# STM32MP23_CM33 register map
File version: 1.2
CPU: CM33 r0p1, little endian, MPU, FPU, vendor SysTick, 8 interrupt priority bits
Registers are 32-bit, read-write, reset 0x0 unless marked. A register's access mark holds for its fields unless they carry their own. Offsets are from the block's base; [hi:lo] are bit positions; {n}, {i} and the like mark numbered series; 'fields as' and 'values as' point back to an identical list.

## RAMCFG — RAMCFG register bank
Base 0x42070000
Same registers: RAMCFG_S 0x52070000
0x00 RAMCFG_SYSRAMCR — RAMCFG SYSRAM control register
  [8] SRAMER — SRAM erase This bit can be set by software only after writing the unlock sequence in ERASEKEY of RAMCFG_SYSRAMERASEKEY. Setting this bit starts the SRAM erase. This bit is automatically cleared by hardware at the end of the erase operation.
    0=No erase operation ongoing; 1=Erase operation ongoing
0x08 RAMCFG_SYSRAMISR ro — RAMCFG SYSRAM interrupt status register
  [8] SRAMBUSY — SRAM busy with erase operation Note: Depending on the SRAM, the erase operation can be performed due to software request, system reset if the option is not disabled by software and tamper detection. Refer to Table73: Internal SRAM features.
    0=No erase operation ongoing; 1=Erase operation ongoing
0x28 RAMCFG_SYSRAMERKEYR wo — RAMCFG SYSRAM erase key register
  [7:0] ERASEKEY — Erase write protection key The following steps are required to unlock the write protection of SRAMER in RAMCFG_SYSRAMCR. a) Write 0xCA into ERASEKEY[7:0]. b) Write 0x53 into ERASEKEY[7:0]. Note: Writing a wrong key reactivates the write protection.
0x80 RAMCFG_SRAM1CR — RAMCFG SRAM1 control register
  [8] SRAMER — SRAM erase. This bit can be set by software only after writing the unlock sequence in ERASEKEY of RAMCFG_MCURAM1ERASEKEY. Setting this bit starts the SRAM erase. This bit is automatically cleared by hardware at the end of the erase operation.
    0=No erase operation ongoing; 1=Erase operation ongoing
0x88 RAMCFG_SRAM1ISR ro — RAMCFG SRAM1 interrupt status register
  fields as RAMCFG_SYSRAMISR
0xA8 RAMCFG_SRAM1ERKEYR wo — RAMCFG SRAM1 erase key register
  [7:0] ERASEKEY — Erase write protection key The following steps are required to unlock the write protection of SRAMER in RAMCFG_MCURAM1CR. a) Write 0xCA into ERASEKEY[7:0]. b) Write 0x53 into ERASEKEY[7:0]. Note: Writing a wrong key reactivates the write protection.
0x100 RAMCFG_SRAM2CR — RAMCFG SRAM2 control register
  [8] SRAMER — SRAM erase. This bit can be set by software only after writing the unlock sequence in ERASEKEY of RAMCFG_MCURAM2ERASEKEY. Setting this bit starts the SRAM erase. This bit is automatically cleared by hardware at the end of the erase operation.
    0=No erase operation ongoing; 1=Erase operation ongoing
0x108 RAMCFG_SRAM2ISR ro — RAMCFG SRAM2 interrupt status register
  [8] SRAMBUSY — SRAM busy with erase operation Note: Depending on the SRAM, the erase operation can be performed due to software request, system reset if the option is not disabled by software and tamper detection. Refer to Table73: Internal SRAM features.
    0=No erase operation on going; 1=Erase operation on going
0x128 RAMCFG_SRAM2ERKEYR wo — RAMCFG SRAM2 erase key register
  [7:0] ERASEKEY — Erase write protection key The following steps are required to unlock the write protection of SRAMER in RAMCFG_MCURAM2CR. a) Write 0xCA into ERASEKEY[7:0]. b) Write 0x53 into ERASEKEY[7:0]. Note: Writing a wrong key reactivates the write protection.
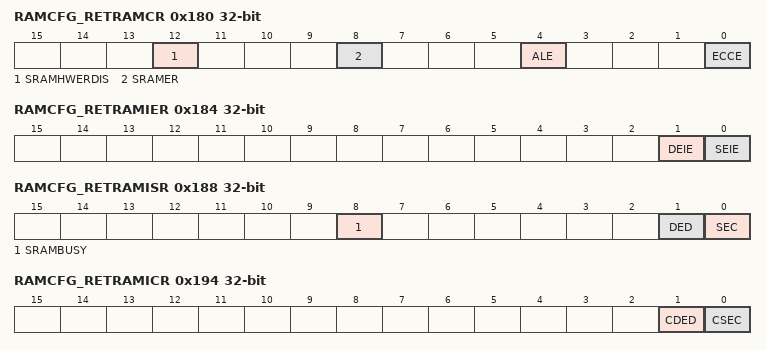
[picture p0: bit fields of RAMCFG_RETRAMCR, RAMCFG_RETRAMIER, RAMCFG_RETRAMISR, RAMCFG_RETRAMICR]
0x180 RAMCFG_RETRAMCR — RAMCFG RETRAM control register
  [12] SRAMHWERDIS — SRAM hardware erase disable Note: This bit is reset on a reset only by VSW POR and VSWRST.
    0=Erase operation done after a system reset; 1=No erase operation done after a system reset
  [8] SRAMER — SRAM erase. This bit can be set by software only after writing the unlock sequence in ERASEKEY of RAMCFG_RETRAMERASEKEY. Setting this bit starts the SRAM erase. This bit is automatically cleared by hardware at the end of the erase operation. Note: This bit is reset on any system reset.
    0=No erase operation ongoing; 1=Erase operation ongoing
  [4] ALE — Address latch enable Note: This bit is reset on any system reset.
    0=Failing address not stored in the RETRAMECC single/double error address registers; 1=Failing address stored in the RETRAMECC single/double error address registers
  [0] ECCE — ECC enable When set, this bit can be cleared by software only after writing the unlock sequence inRAMCFG_RETRAMECCKEYR. Note: This bit is reset on an application reset.
    0=ECC disabled; 1=ECC enabled
0x184 RAMCFG_RETRAMIER — RAMCFG RETRAM interrupt enable register
  [1] DEIE — ECC double error interrupt enable
    0=Double error interrupt disabled; 1=Double error interrupt enabled
  [0] SEIE — ECC single error interrupt enable
    0=Single error interrupt disabled; 1=Single error interrupt enabled
0x188 RAMCFG_RETRAMISR ro — RAMCFG RETRAM interrupt status register
  [8] SRAMBUSY — SRAM busy with erase operation Note: Depending on the SRAM, the erase operation can be performed due to software request, system reset if the option is not disabled by software and tamper detection. Refer to Table73: Internal SRAM features.
    0=No erase operation ongoing; 1=Erase operation ongoing
  [1] DED — ECC double error detected
    0=No double error; 1=Double error detected
  [0] SEC — ECC single error corrected
    0=No single error; 1=Single error corrected
0x18C RAMCFG_RETRAMSEAR ro — RAMCFG RETRAM ECC single error address register
  [14:0] ESEA — ECC single error address When ALE is set in RAMCFG_RETRAMCR, this bit field is updated with the word-address corresponding to the ECC single error.
0x190 RAMCFG_RETRAMDEAR ro — RAMCFG RETRAM ECC double error address register
  [14:0] EDEA — ECC double error address When ALE is set in RAMCFG_RETRAMCR, this bit field is updated with the word-address corresponding to the ECC double error.
0x194 RAMCFG_RETRAMICR wo — RAMCFG RETRAM interrupt clear flag register
  [1] CDED — Clear of ECC double error detected Writing 1 to this flag clears DED in RAMCFG_RETRAMISR.
  [0] CSEC — Clear of ECC single corrected Writing 1 to this flag clears SEC in RAMCFG_RETRAMISR.
0x1A4 RAMCFG_RETRAMECCKEYR wo — RAMCFG RETRAM ECC key register
  [7:0] ECCKEY — ECC write protection key The following steps are required to unlock the write protection of ECCE in RAMCFG_RETRAMCR. a) Write 0xAE into ECCKEY[7:0]. b) Write 0x75 into ECCKEY[7:0]. Note: Writing a wrong key reactivates the write protection.
0x1A8 RAMCFG_RETRAMERKEYR wo — RAMCFG RETRAM erase key register
  [7:0] ERASEKEY — Erase write protection key The following steps are required to unlock the write protection of SRAMER in RAMCFG_RETRAMCR. a) Write 0xCA into ERASEKEY[7:0]. b) Write 0x53 into ERASEKEY[7:0]. Note: Writing a wrong key reactivates the write protection.
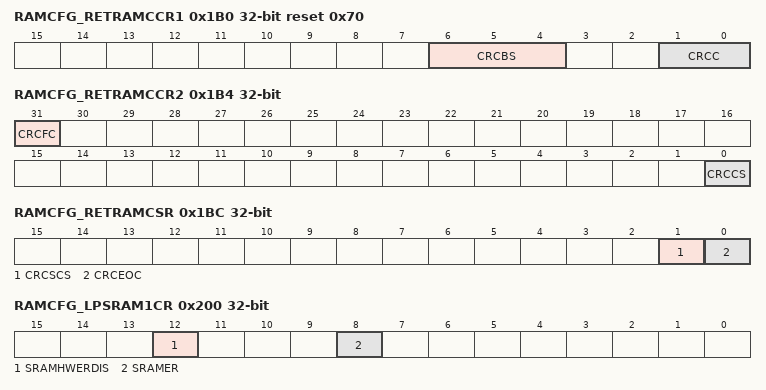
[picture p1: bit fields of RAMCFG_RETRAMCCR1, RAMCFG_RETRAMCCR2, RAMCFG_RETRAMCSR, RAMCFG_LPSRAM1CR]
0x1B0 RAMCFG_RETRAMCCR1 reset 0x70 — RAMCFG RETRAM CRC control register 1
  [6:4] CRCBS — CRC buffer size This bit field is used to program the buffer size to take into account during CRC computation. Starting from RETRAM start address. .....
    0=16 Kbytes; 1=32 Kbytes; 2=48 Kbytes; 7=128 Kbytes (default)
  [1:0] CRCC — CRC configuration. in RAMCFG_RETRAMCCSR when the CRCEOC flag is set.
    0=CRC disabled; 1=CRC computation enabled. The calculated signature is stored; 2=CRC computation and signature check enabled. The status of the signature check is available in RAMCFG_RETRAMCSR when the CRCEOC flag is set.
0x1B4 RAMCFG_RETRAMCCR2 — RAMCFG RETRAM CRC control register 2
  [31] CRCFC — CRC flags clear. Setting this bit clears the CRC status flags in RAMCFG_RETRAMCSR. Note: This bit is automatically cleared by hardware.
    0=CRC flags are not affected; 1=CRC flags are cleared in RAMCFG_RETRAMCSR
  [0] CRCCS — CRC computation start Setting this bit starts the CRC computation. This bit is automatically cleared by hardware at the end of the CRC computation phase.
    0=CRC computation not launched; 1=CRC computation launched
0x1B8 RAMCFG_RETRAMCRSR — RAMCFG RETRAM CRC reference signature register
  [31:0] CRCRS — CRC reference signature. This bit field is used to write the reference signature (precalculated signature) used for CRC signature comparison check.
0x1BC RAMCFG_RETRAMCSR ro — RAMCFG RETRAM CRC status register
  [1] CRCSCS — CRC signature check status flag This bit is set when the computed signature matches the reference signature stored in RAMCFG_RETRAMCRSR. This bit is valid only when the CRCEOC flag is set.
    0=Fault detected is SRAM data. Calculated signature does not match the reference signature.; 1=SRAM data is correct. Calculated signature matches the reference signature.
  [0] CRCEOC — CRC end-of-computation flag
    0=Computation ongoing; 1=Computation done
0x1C0 RAMCFG_RETRAMCCSR ro — RAMCFG RETRAM CRC calculated signature register
  [31:0] CRCCS — CRC calculated signature When CRCEOC is set in RAMCFG_RETRAMCSR, this bit field is updated with the calculate signature representing the content of the SRAM buffer to compute.
0x200 RAMCFG_LPSRAM1CR — RAMCFG LPSRAM1 control register
  [12] SRAMHWERDIS — SRAM hardware erase disable Note: This bit is reset on a reset only by VSW POR and VSWRST.
    0=Erase operation done after a D3 domain reset; 1=No erase operation done after a D3 domain reset
  [8] SRAMER — SRAM erase. This bit can be set by software only after writing the unlock sequence in ERASEKEY of RAMCFG_LPSRAM1ERASEKEY. Setting this bit starts the SRAM erase. This bit is automatically cleared by hardware at the end of the erase operation. Note: This bit is reset on any system reset.
    0=No erase operation ongoing; 1=Erase operation ongoing
{0x188+0x80*i} RAMCFG_LPSRAM{i}ISR ro (i=1..3) — RAMCFG LPSRAM{i} interrupt status register
  fields as RAMCFG_SYSRAMISR
{0x1A8+0x80*i} RAMCFG_LPSRAM{i}ERKEYR wo (i=1..3) — RAMCFG LPSRAM{i} erase key register
  [7:0] ERASEKEY — Erase write protection key The following steps are required to unlock the write protection of SRAMER in RAMCFG_LPSRAM{i}CR. a) Write 0xCA into ERASEKEY[7:0]. b) Write 0x53 into ERASEKEY[7:0]. Note: Writing a wrong key reactivates the write protection.
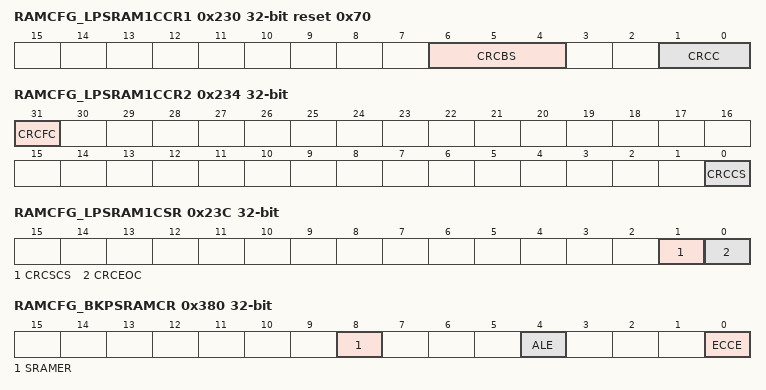
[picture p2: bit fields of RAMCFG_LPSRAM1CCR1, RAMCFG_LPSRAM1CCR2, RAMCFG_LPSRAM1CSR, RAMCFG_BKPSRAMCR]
0x230 RAMCFG_LPSRAM1CCR1 reset 0x70 — RAMCFG LPSRAM1 CRC control register 1
  [6:4] CRCBS — CRC buffer size This bit field is used to program the buffer size to take into account during CRC computation. Starting from LPSRAM1 start address. .....
    0=1 Kbyte; 1=2 Kbytes; 2=3 Kbytes; 7=8 Kbytes (default)
  [1:0] CRCC — CRC configuration. in RAMCFG_LPSRAM1CCSR when the CRCEOC flag is set.
    0=CRC disabled; 1=CRC computation enabled. The calculated signature is stored; 2=CRC computation and signature check enabled. The status of the signature check is available in RAMCFG_LPSRAM1CSR when the CRCEOC flag is set.
0x234 RAMCFG_LPSRAM1CCR2 — RAMCFG LPSRAM1 CRC control register 2
  [31] CRCFC — CRC flags clear. Setting this bit clears the CRC status flags C in RAMCFG_LPSRAM1CSR. Note: This bit is automatically cleared by hardware.
    0=CRC flags are not affected; 1=CRC flags are cleared in RAMCFG_LPSRAM1CSR
  [0] CRCCS — CRC computation start Setting this bit starts the CRC computation. This bit is automatically cleared by hardware at the end of the CRC computation phase.
    0=CRC computation not launched; 1=CRC computation launched
0x238 RAMCFG_LPSRAM1CRSR — RAMCFG LPSRAM1 CRC reference signature register
  fields as RAMCFG_RETRAMCRSR
0x23C RAMCFG_LPSRAM1CSR ro — RAMCFG LPSRAM1 CRC status register
  [1] CRCSCS — CRC signature check status flag This bit is set when the computed signature matches the reference signature stored in RAMCFG_LPSRAM1CRSR. This field is valid only when the CRCEOC flag is set.
    0=Fault detected is SRAM data. Calculated signature does not matching the reference signature.; 1=SRAM data is correct. Calculated signature matches the reference signature.
  [0] CRCEOC — CRC end of computation flag
    0=Computation ongoing; 1=Computation done
0x240 RAMCFG_LPSRAM1CCSR ro — RAMCFG LPSRAM1 CRC calculated signature register
  [31:0] CRCCS — CRC calculated signature When CRCEOC is set in RAMCFG_LPSRAM1CSR, this field is updated with the calculate signature representing the content of the SRAM buffer to compute.
0x280 RAMCFG_LPSRAM2CR — RAMCFG LPSRAM2 control register
  [8] SRAMER — SRAM erase. This bit can be set by software only after writing the unlock sequence in the ERASEKEY field of RAMCFG_LPSRAM2ERASEKEY. Setting this bit starts the SRAM erase. This bit is automatically cleared by hardware at the end of the erase operation.
    0=No erase operation ongoing; 1=Erase operation ongoing
0x300 RAMCFG_LPSRAM3CR — RAMCFG LPSRAM3 control register
  [8] SRAMER — SRAM erase. This bit can be set by software only after writing the unlock sequence in ERASEKEY of RAMCFG_LPSRAM3ERASEKEY. Setting this bit starts the SRAM erase. This bit is automatically cleared by hardware at the end of the erase operation.
    0=No erase operation ongoing; 1=Erase operation ongoing
0x380 RAMCFG_BKPSRAMCR — RAMCFG BKPSRAM control register
  [8] SRAMER — SRAM erase. This bit can be set by software only after writing the unlock sequence in ERASEKEY of RAMCFG_BKPSRAMERASEKEY. Setting this bit starts the SRAM erase. This bit is automatically cleared by hardware at the end of the erase operation.
    0=No erase operation ongoing; 1=Erase operation ongoing
  [4] ALE — Address latch enable
    0=Failing address not stored in the BKPSRAMECC single/double error address registers; 1=Failing address stored in the BKPSRAMECC single/double error address registers
  [0] ECCE — ECC enable When set, this bit can be cleared by software only after writing the unlock sequence in RAMCFG_BKPSRAMECCKEYR.
    0=ECC disabled; 1=ECC enabled
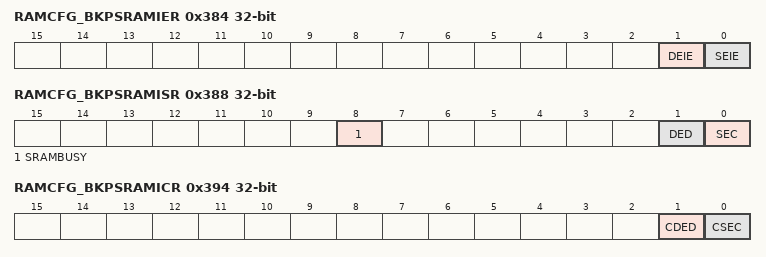
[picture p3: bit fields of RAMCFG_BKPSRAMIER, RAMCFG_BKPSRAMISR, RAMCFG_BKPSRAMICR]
0x384 RAMCFG_BKPSRAMIER — RAMCFG BKPSRAM interrupt enable register
  [1] DEIE — ECC double-error interrupt enable
    0=Double-error interrupt disabled; 1=Double-error interrupt enabled
  [0] SEIE — ECC single-error interrupt enable
    0=Single-error interrupt disabled; 1=Single-error interrupt enabled
0x388 RAMCFG_BKPSRAMISR ro — RAMCFG BKPSRAM interrupt status register
  [8] SRAMBUSY — SRAM busy with erase operation Note: Depending on the SRAM, the erase operation can be performed due to software request, system reset if the option is not disabled by software and tamper detection. Refer to Table73: Internal SRAM features.
    0=No erase operation ongoing; 1=Erase operation ongoing
  [1] DED — ECC double error detected
    0=No double error; 1=Double error detected
  [0] SEC — ECC single error corrected
    0=No single error; 1=Single error detected and corrected
0x38C RAMCFG_BKPSRAMEEAR ro — RAMCFG BKPSRAM ECC single error address register
  [10:0] ESEA — ECC single error address When ALE is set in RAMCFG_BKPSRAMCR, this field is updated with the word-address corresponding to the ECC single error.
0x390 RAMCFG_BKPSRAMDEAR ro — RAMCFG BKPSRAM ECC double error address register
  [10:0] EDEA — ECC double error address When ALE is set in RAMCFG_BKPSRAMCR, this bit field is updated with the word-address corresponding to the ECC double error.
0x394 RAMCFG_BKPSRAMICR wo — RAMCFG BKPSRAM interrupt clear flag register
  [1] CDED — Clear of ECC double error detected Writing 1 to this flag clears DED in RAMCFG_BKPSRAMISR.
  [0] CSEC — Clear of ECC single corrected Writing 1 to this flag clears SEC in RAMCFG_BKPSRAMISR.
0x3A4 RAMCFG_BKPSRAMECCKEYR wo — RAMCFG BKPSRAM ECC key register
  [7:0] ECCKEY — ECC write protection key The following steps are required to unlock the write protection of ECCE in RAMCFG_BKPSRAMCR. a) Write 0xAE into ECCKEY[7:0]. b) Write 0x75 into ECCKEY[7:0]. Note: Writing a wrong key reactivates the write protection.
0x3A8 RAMCFG_BKPSRAMERKEYR wo — RAMCFG BKPSRAM erase key register
  [7:0] ERASEKEY — Erase write protection key The following steps are required to unlock the write protection of SRAMER in RAMCFG_BKPSRAMCR. a) Write 0xCA into ERASEKEY[7:0]. b) Write 0x53 into ERASEKEY[7:0]. Note: Writing a wrong key reactivates the write protection.
0x400 RAMCFG_VDERAMCR — RAMCFG VDERAM control register
  [8] SRAMER — SRAM erase This bit can be set by software only after writing the unlock sequence in ERASEKEY of RAMCFG_VDERAMERASEKEY. Setting this bit starts the SRAM erase. This bit is automatically cleared by hardware at the end of the erase operation. Note: This bit is reset on any system reset.
    0=No erase operation ongoing; 1=Erase operation ongoing
0x408 RAMCFG_VDERAMISR ro — RAMCFG VDERAM interrupt status register
  fields as RAMCFG_SYSRAMISR
0x428 RAMCFG_VDERAMERKEYR wo — RAMCFG VDERAM erase key register
  [7:0] ERASEKEY — Erase write protection key The following steps are required to unlock the write protection of SRAMER in RAMCFG_VDERAMCR. a) Write 0xCA into ERASEKEY[7:0]. b) Write 0x53 into ERASEKEY[7:0]. Note: Writing a wrong key reactivates the write protection.
